# EFM32GG990F1024 register map
File version: 1.6
Registers are 32-bit, read-write, reset 0x0 unless marked. A register's access mark holds for its fields unless they carry their own. Offsets are from the block's base; [hi:lo] are bit positions; {n}, {i} and the like mark numbered series; 'fields as' and 'values as' point back to an identical list.

## LESENSE
Base 0x4008C000
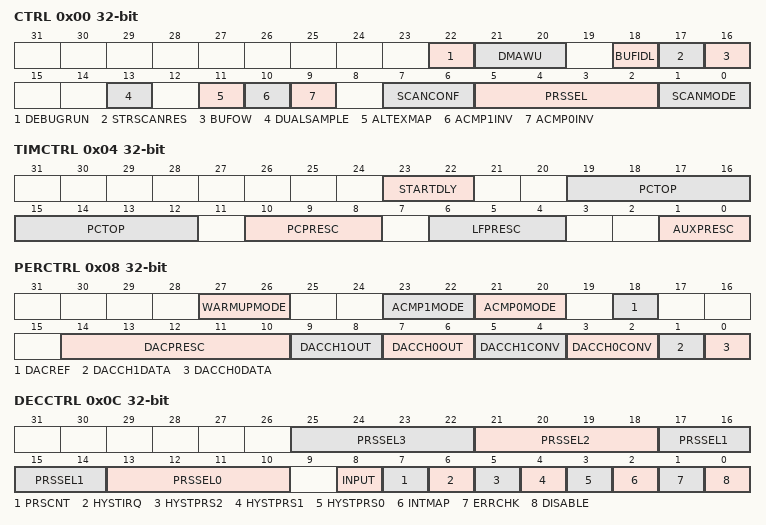
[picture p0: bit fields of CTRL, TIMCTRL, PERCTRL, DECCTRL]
0x00 CTRL — Control Register
  [22] DEBUGRUN — Debug Mode Run Enable
  [21:20] DMAWU — DMA wakeup from EM2
    0=DISABLE (No DMA wakeup from EM2); 1=BUFDATAV (DMA wakeup from EM2 when data is valid in the result buffer); 2=BUFLEVEL (DMA wakeup from EM2 when the result buffer is full/halffull depending on BUFIDL configuration)
  [18] BUFIDL — Result buffer interrupt and DMA trigger level
  [17] STRSCANRES — Enable storing of SCANRES
  [16] BUFOW — Result buffer overwrite
  [13] DUALSAMPLE — Enable dual sample mode
  [11] ALTEXMAP — Alternative excitation map
  [10] ACMP1INV — Invert analog comparator 1 output
  [9] ACMP0INV — Invert analog comparator 0 output
  [7:6] SCANCONF — Select scan configuration
    0=DIRMAP (The channel configuration register registers used are directly mapped to the channel number.); 1=INVMAP (The channel configuration register registers used are CHX+8_CONF for channels 0-7 and CHX-8_CONF for channels 8-15.); 2=TOGGLE (The channel configuration register registers used toggles between CHX_CONF and CHX+8_CONF when channel x triggers); 3=DECDEF (The decoder state defines the CONF registers to be used.)
  [5:2] PRSSEL — Scan start PRS select
    {v}=PRSCH{v} (PRS Channel {v} selected as input) (v=0..11)
  [1:0] SCANMODE — Configure scan mode
    0=PERIODIC (A new scan is started each time the period counter overflows); 1=ONESHOT (A single scan is performed when START in CMD is set); 2=PRS (Pulse on PRS channel)
0x04 TIMCTRL — Timing Control Register
  [23:22] STARTDLY — Start delay configuration
  [19:12] PCTOP — Period counter top value
  [10:8] PCPRESC — Period counter prescaling
    0=DIV1 (The period counter clock frequency is LFACLKLESENSE/1); 1=DIV2 (The period counter clock frequency is LFACLKLESENSE/2); 2=DIV4 (The period counter clock frequency is LFACLKLESENSE/4); 3=DIV8 (The period counter clock frequency is LFACLKLESENSE/8); 4=DIV16 (The period counter clock frequency is LFACLKLESENSE/16); 5=DIV32 (The period counter clock frequency is LFACLKLESENSE/32); 6=DIV64 (The period counter clock frequency is LFACLKLESENSE/64); 7=DIV128 (The period counter clock frequency is LFACLKLESENSE/128)
  [6:4] LFPRESC — Prescaling factor for low frequency timer
    0=DIV1 (Low frequency timer is clocked with LFACLKLESENSE/1); 1=DIV2 (Low frequency timer is clocked with LFACLKLESENSE/2); 2=DIV4 (Low frequency timer is clocked with LFACLKLESENSE/4); 3=DIV8 (Low frequency timer is clocked with LFACLKLESENSE/8); 4=DIV16 (Low frequency timer is clocked with LFACLKLESENSE/16); 5=DIV32 (Low frequency timer is clocked with LFACLKLESENSE/32); 6=DIV64 (Low frequency timer is clocked with LFACLKLESENSE/64); 7=DIV128 (Low frequency timer is clocked with LFACLKLESENSE/128)
  [1:0] AUXPRESC — Prescaling factor for high frequency timer
    0=DIV1 (High frequency timer is clocked with AUXHFRCO/1); 1=DIV2 (High frequency timer is clocked with AUXHFRCO/2); 2=DIV4 (High frequency timer is clocked with AUXHFRCO/4); 3=DIV8 (High frequency timer is clocked with AUXHFRCO/8)
0x08 PERCTRL — Peripheral Control Register
  [27:26] WARMUPMODE — ACMP and DAC duty cycle mode
    0=NORMAL (The analog comparators and DAC are shut down when LESENSE is idle); 1=KEEPACMPWARM (The analog comparators are kept powered up when LESENSE is idle); 2=KEEPDACWARM (The DAC is kept powered up when LESENSE is idle); 3=KEEPACMPDACWARM (The analog comparators and DAC are kept powered up when LESENSE is idle)
  [23:22] ACMP1MODE
    0=DISABLE (LESENSE does not control ACMP1); 1=MUX (LESENSE controls the input mux (POSSEL) of ACMP1); 2=MUXTHRES (LESENSE controls the input mux and the threshold value (VDDLEVEL) of ACMP1)
  [21:20] ACMP0MODE
    0=DISABLE (LESENSE does not control ACMP0); 1=MUX (LESENSE controls the input mux (POSSEL) of ACMP0); 2=MUXTHRES (LESENSE controls the input mux (POSSEL) and the threshold value (VDDLEVEL) of ACMP0)
  [18] DACREF — DAC bandgap reference used
  [14:10] DACPRESC — DAC prescaler configuration.
  [9:8] DACCH1OUT — DAC channel 1 output mode
    0=DISABLE (DAC CH1 output to pin and ACMP/ADC disabled); 1=PIN (DAC CH1 output to pin enabled, output to ADC and ACMP disabled); 2=ADCACMP (DAC CH1 output to pin disabled, output to ADC and ACMP enabled); 3=PINADCACMP (DAC CH1 output to pin, ADC, and ACMP enabled.)
  [7:6] DACCH0OUT — DAC channel 0 output mode
    0=DISABLE (DAC CH0 output to pin and ACMP/ADC disabled); 1=PIN (DAC CH0 output to pin enabled, output to ADC and ACMP disabled); 2=ADCACMP (DAC CH0 output to pin disabled, output to ADC and ACMP enabled); 3=PINADCACMP (DAC CH0 output to pin, ADC, and ACMP enabled.)
  [5:4] DACCH1CONV — DAC channel 1 conversion mode
    0=DISABLE (LESENSE does not control DAC CH1.); 1=CONTINUOUS (DAC channel 1 is driven in continuous mode.); 2=SAMPLEHOLD (DAC channel 1 is driven in sample hold mode.); 3=SAMPLEOFF (DAC channel 1 is driven in sample off mode.)
  [3:2] DACCH0CONV — DAC channel 0 conversion mode
    0=DISABLE (LESENSE does not control DAC CH0.); 1=CONTINUOUS (DAC channel 0 is driven in continuous mode.); 2=SAMPLEHOLD (DAC channel 0 is driven in sample hold mode.); 3=SAMPLEOFF (DAC channel 0 is driven in sample off mode.)
  [1] DACCH1DATA — DAC CH1 data selection.
  [0] DACCH0DATA — DAC CH0 data selection.
0x0C DECCTRL — Decoder control Register
  [4n+13:4n+10] PRSSEL{n} (n=0..3)
    {v}=PRSCH{v} (PRS Channel {v} selected as input) (v=0..11)
  [8] INPUT
  [7] PRSCNT — Enable count mode on decoder PRS channels 0 and 1
  [6] HYSTIRQ — Enable decoder hysteresis on interrupt requests
  [5] HYSTPRS2 — Enable decoder hysteresis on PRS2 output
  [4] HYSTPRS1 — Enable decoder hysteresis on PRS1 output
  [3] HYSTPRS0 — Enable decoder hysteresis on PRS0 output
  [2] INTMAP — Enable decoder to channel interrupt mapping
  [1] ERRCHK — Enable check of current state
  [0] DISABLE — Disable the decoder
0x10 BIASCTRL — Bias Control Register
  [1:0] BIASMODE — Select bias mode
    0=DUTYCYCLE (Bias module duty cycled between low power and high accuracy mode); 1=HIGHACC (Bias module always in high accuracy mode); 2=DONTTOUCH (Bias module is controlled by the EMU and not affected by LESENSE)
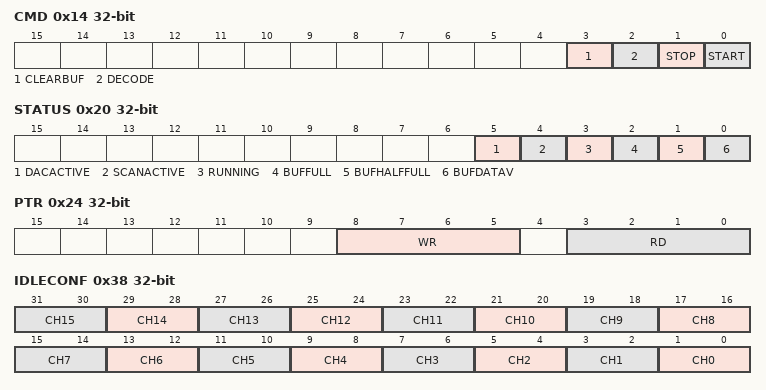
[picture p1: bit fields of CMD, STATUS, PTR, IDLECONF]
0x14 CMD wo — Command Register
  [3] CLEARBUF — Clear result buffer
  [2] DECODE — Start decoder
  [1] STOP — Stop scanning of sensors
  [0] START — Start scanning of sensors.
0x18 CHEN — Channel enable Register
  [15:0] CHEN — Enable scan channel
0x1C SCANRES ro — Scan result register
  [15:0] SCANRES — Scan results
0x20 STATUS ro
  [5] DACACTIVE — LESENSE DAC interface is active
  [4] SCANACTIVE — LESENSE is currently interfacing sensors.
  [3] RUNNING — LESENSE is active
  [2] BUFFULL — Result buffer full
  [1] BUFHALFFULL — Result buffer half full
  [0] BUFDATAV — Result data valid
0x24 PTR ro — Result buffer pointers
  [8:5] WR — Result buffer write pointer.
  [3:0] RD — Result buffer read pointer.
0x28 BUFDATA ro read-has-side-effects — Result buffer data register
  [15:0] BUFDATA — Result data
0x2C CURCH ro — Current channel index
  [3:0] CURCH — Shows the index of the current channel
0x30 DECSTATE — Current decoder state
  [3:0] DECSTATE — Shows the current decoder state
0x34 SENSORSTATE — Decoder input register
  [3:0] SENSORSTATE — Shows the status of sensors chosen as input to the decoder
0x38 IDLECONF — GPIO Idlephase configuration
  [2n+1:2n] CH{n} (n=12..15) — Channel {n} idlephase configuration
    0=DISABLE (CH{n} output is disabled in idle phase); 1=HIGH (CH{n} output is high in idle phase); 2=LOW (CH{n} output is low in idle phase); 3=DACCH1 (CH{n} output is connected to DAC CH1 output in idle phase)
  [2n+1:2n] CH{n} (n=4..11) — Channel {n} idlephase configuration
    0=DISABLE (CH{n} output is disabled in idle phase); 1=HIGH (CH{n} output is high in idle phase); 2=LOW (CH{n} output is low in idle phase)
  [2n+1:2n] CH{n} (n=0..3) — Channel {n} idlephase configuration
    0=DISABLE (CH{n} output is disabled in idle phase); 1=HIGH (CH{n} output is high in idle phase); 2=LOW (CH{n} output is low in idle phase); 3=DACCH0 (CH{n} output is connected to DAC CH0 output in idle phase)
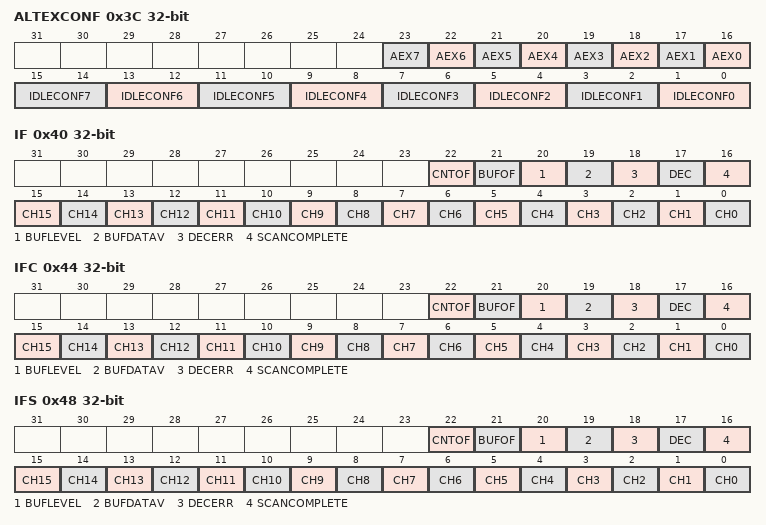
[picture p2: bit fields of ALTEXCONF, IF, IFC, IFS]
0x3C ALTEXCONF — Alternative excite pin configuration
  [n+16] AEX{n} (n=0..7) — ALTEX{n} always excite enable
  [2n+1:2n] IDLECONF{n} (n=0..7) — ALTEX{n} idle phase configuration
    0=DISABLE (ALTEX{n} output is disabled in idle phase); 1=HIGH (ALTEX{n} output is high in idle phase); 2=LOW (ALTEX{n} output is low in idle phase)
0x40 IF ro — Interrupt Flag Register
  [22] CNTOF, [21] BUFOF, [20] BUFLEVEL, [19] BUFDATAV, [18] DECERR, [17] DEC, [16] SCANCOMPLETE, [n] CH{n} (n=0..15)
0x44 IFC wo — Interrupt Flag Clear Register
  fields as IF
0x48 IFS wo — Interrupt Flag Set Register
  fields as IF
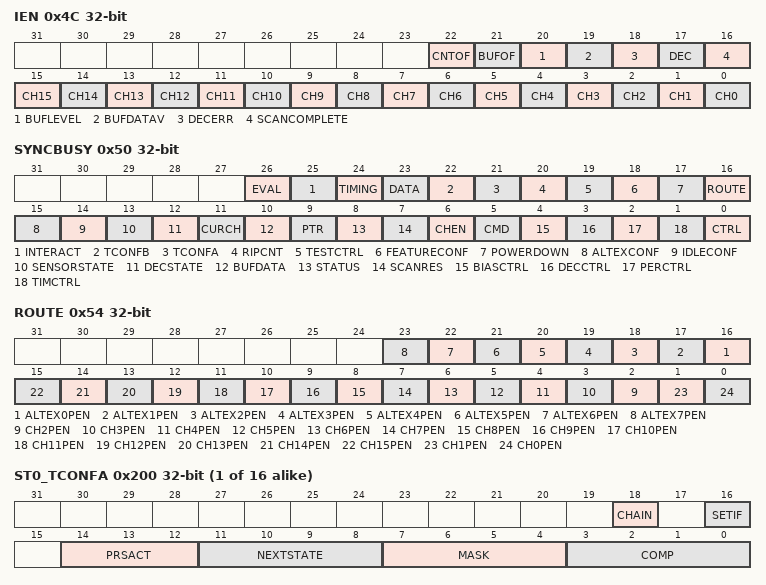
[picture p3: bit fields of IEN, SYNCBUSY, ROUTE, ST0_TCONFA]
0x4C IEN — Interrupt Enable Register
  fields as IF
0x50 SYNCBUSY ro — Synchronization Busy Register
  [26] EVAL — LESENSE_CHx_EVAL Register Busy
  [25] INTERACT — LESENSE_CHx_INTERACT Register Busy
  [24] TIMING — LESENSE_CHx_TIMING Register Busy
  [23] DATA — LESENSE_BUFx_DATA Register Busy
  [22] TCONFB — LESENSE_STx_TCONFB Register Busy
  [21] TCONFA — LESENSE_STx_TCONFA Register Busy
  [20] RIPCNT — LESENSE_RIPCNT Register Busy
  [19] TESTCTRL — LESENSE_TESTCTRL Register Busy
  [18] FEATURECONF — LESENSE_FEATURECONF Register Busy
  [17] POWERDOWN — LESENSE_POWERDOWN Register Busy
  [16] ROUTE — LESENSE_ROUTE Register Busy
  [15] ALTEXCONF — LESENSE_ALTEXCONF Register Busy
  [14] IDLECONF — LESENSE_IDLECONF Register Busy
  [13] SENSORSTATE — LESENSE_SENSORSTATE Register Busy
  [12] DECSTATE — LESENSE_DECSTATE Register Busy
  [11] CURCH — LESENSE_CURCH Register Busy
  [10] BUFDATA — LESENSE_BUFDATA Register Busy
  [9] PTR — LESENSE_PTR Register Busy
  [8] STATUS — LESENSE_STATUS Register Busy
  [7] SCANRES — LESENSE_SCANRES Register Busy
  [6] CHEN — LESENSE_CHEN Register Busy
  [5] CMD — LESENSE_CMD Register Busy
  [4] BIASCTRL — LESENSE_BIASCTRL Register Busy
  [3] DECCTRL — LESENSE_DECCTRL Register Busy
  [2] PERCTRL — LESENSE_PERCTRL Register Busy
  [1] TIMCTRL — LESENSE_TIMCTRL Register Busy
  [0] CTRL — LESENSE_CTRL Register Busy
0x54 ROUTE — I/O Routing Register
  [n+16] ALTEX{n}PEN (n=0..7) — ALTEX{n} Pin Enable
  [n] CH{n}PEN (n=2..15) — CH{n} Pin Enable
  [1] CH1PEN — CH0 Pin Enable
  [0] CH0PEN — CH0 Pin Enable
0x58 POWERDOWN — LESENSE RAM power-down resgister
  [0] RAM — LESENSE RAM power-down
{0x200+8i} ST{i}_TCONFA (i=0..15) — State transition configuration A
  [18] CHAIN — Enable state descriptor chaining
  [16] SETIF — Set interrupt flag enable
  [14:12] PRSACT — Configure transition action
  [11:8] NEXTSTATE — Next state index
  [7:4] MASK — Sensor mask
  [3:0] COMP — Sensor compare value
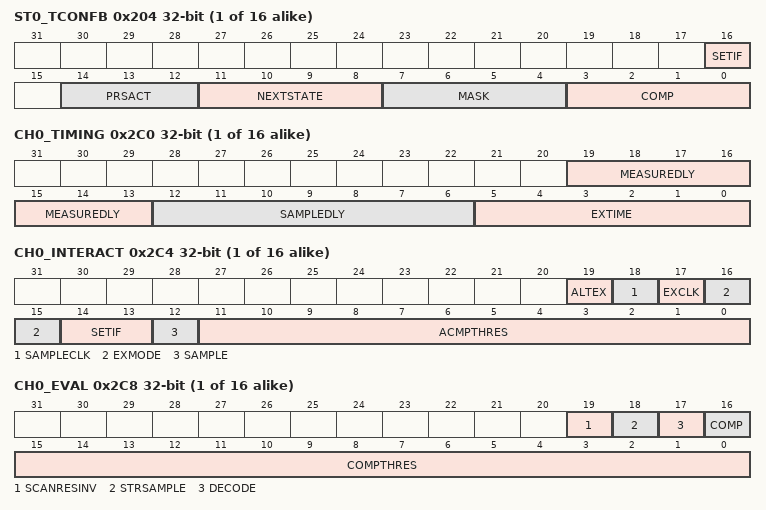
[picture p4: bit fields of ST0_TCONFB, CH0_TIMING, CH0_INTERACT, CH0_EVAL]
{0x204+8i} ST{i}_TCONFB (i=0..15) — State transition configuration B
  [16] SETIF — Set interrupt flag
  [14:12] PRSACT — Configure transition action
  [11:8] NEXTSTATE — Next state index
  [7:4] MASK — Sensor mask
  [3:0] COMP — Sensor compare value
{0x280+4i} BUF{i}_DATA (i=0..15) — Scan results
  [15:0] DATA — Scan result buffer
{0x2C0+0x10*i} CH{i}_TIMING (i=0..15) — Scan configuration
  [19:13] MEASUREDLY — Set measure delay
  [12:6] SAMPLEDLY — Set sample delay
  [5:0] EXTIME — Set excitation time
{0x2C4+0x10*i} CH{i}_INTERACT (i=0..15) — Scan configuration
  [19] ALTEX — Use alternative excite pin
  [18] SAMPLECLK — Select clock used for timing of sample delay
  [17] EXCLK — Select clock used for excitation timing
  [16:15] EXMODE — Set GPIO mode
    0=DISABLE (Disabled); 1=HIGH (Push Pull, GPIO is driven high); 2=LOW (Push Pull, GPIO is driven low); 3=DACOUT (DAC output)
  [14:13] SETIF — Enable interrupt generation
    0=NONE (No interrupt is generated); 1=LEVEL (Set interrupt flag if the sensor triggers.); 2=POSEDGE (Set interrupt flag on positive edge on the sensor state); 3=NEGEDGE (Set interrupt flag on negative edge on the sensor state)
  [12] SAMPLE — Select sample mode
  [11:0] ACMPTHRES — Set ACMP threshold
{0x2C8+0x10*i} CH{i}_EVAL (i=0..15) — Scan configuration
  [19] SCANRESINV — Enable inversion of result
  [18] STRSAMPLE — Select if counter result should be stored
  [17] DECODE — Send result to decoder
  [16] COMP — Select mode for counter comparison
  [15:0] COMPTHRES — Decision threshold for counter
